AUTOSAR XML (schema 4-3-0)
package /Dimmer
  application-sw-component-type:
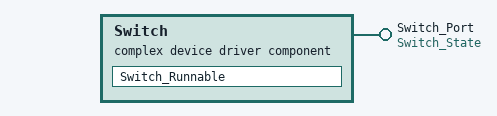
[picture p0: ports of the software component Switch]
    complex device driver sw component type Switch
      provide port Switch_Port: server-com-spec=getSwitchState, provided-interface=Switch_State
      behavior Switch_InternalBehavior
        events:
          init event Switch_Init: start-on-event=Switch_Runnable
        runnable Switch_Runnable
    swc implementation Switch_Implementation: behavior=Switch_InternalBehavior
